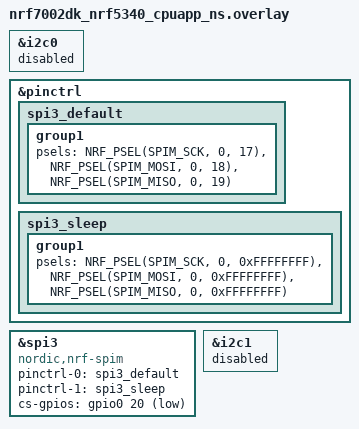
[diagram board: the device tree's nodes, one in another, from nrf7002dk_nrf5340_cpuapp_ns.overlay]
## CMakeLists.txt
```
cmake_minimum_required(VERSION 3.20.0)
find_package(Zephyr REQUIRED HINTS $ENV{ZEPHYR_BASE})
target_include_directories(app PRIVATE ${CMAKE_CURRENT_SOURCE_DIR}/inc)

project(untitled)
set ( SOURCES
      src/main.c
 
)
target_sources(app PRIVATE ${SOURCES})

 
```

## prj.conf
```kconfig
CONFIG_PRINTK=y
CONFIG_SPI=y
CONFIG_GPIO=y
CONFIG_SPI_NRFX=y
```

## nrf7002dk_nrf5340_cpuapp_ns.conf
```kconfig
#UART1 is used for TF-M logging should be disabled
CONFIG_SPI=y
CONFIG_GPIO=y
CONFIG_TFM_SECURE_UART=n
CONFIG_TFM_LOG_LEVEL_SILENCE=y
```

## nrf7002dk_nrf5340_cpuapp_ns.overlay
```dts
/* STEP 2.1 - Add the SPI peripheral to spi1 */
&i2c0 {	status = "disabled";};
//&spi3 {
	//compatible = "nordic,nrf-spim";
    //status = "okay";
    //sck-pin = <17>;  /* SPI Clock Pin */
    //mosi-pin = <18>; /* SPI MOSI Pin */
    //miso-pin = <19>; /* SPI MISO Pin */
    //cs-gpios = <&gpio0 20 GPIO_ACTIVE_LOW>;
//};
//&gpio0 {
//    status = "okay";
//    pinctrl-0 = <&gpio0_pins>;
//    pinctrl-names = "default";
//    cs-gpios = <&gpio0 25 GPIO_ACTIVE_LOW>;  // CS pin, active low
//};

&pinctrl {
    spi3_default: spi3_default {
        group1 {
            psels = <NRF_PSEL(SPIM_SCK, 0, 17)>, /* SCK on pin 17 */
                    <NRF_PSEL(SPIM_MOSI, 0, 18)>, /* MOSI on pin 18 */
                    <NRF_PSEL(SPIM_MISO, 0, 19)>; /* MISO on pin 19 */
        };
    };

    spi3_sleep: spi3_sleep {
        group1 {
            psels = <NRF_PSEL(SPIM_SCK, 0, 0xFFFFFFFF)>, /* Disable SCK */
                    <NRF_PSEL(SPIM_MOSI, 0, 0xFFFFFFFF)>, /* Disable MOSI */
                    <NRF_PSEL(SPIM_MISO, 0, 0xFFFFFFFF)>; /* Disable MISO */
        };
    };
};

&spi3 {
    compatible = "nordic,nrf-spim";
    status = "okay";
    pinctrl-0 = <&spi3_default>;
    pinctrl-1 = <&spi3_sleep>;
    pinctrl-names = "default", "sleep";
    cs-gpios = <&gpio0 20 GPIO_ACTIVE_LOW>; /* Chip Select on GPIO pin 20 */
};


&i2c1 {	status = "disabled";};

/*

&spi1 {
	my_spi_device: my_spi_device@9000 {
      #address-cells = < 0x1 >;
      #size-cells = < 0x0 >;
	    compatible = "nordic,nrf-spim";
      label = "my_spi_device";
		  status = "okay";
		  pinctrl-0 = <&spi1_default>;
		  pinctrl-1 = <&spi1_sleep>;
		  pinctrl-names = "default", "sleep";
      reg = <0x9000 0x1000>;
      interrupts = <0xc 0x1>;
      easydma-maxcnt-bits = < 0x10 >;
      max-frequency= <0x7a1200>;
	  cs-gpios = <&gpio0 5 GPIO_ACTIVE_LOW>;
	};
};

&pinctrl {
	spi1_default: spi1_default {
	cs-gpios = <&gpio0 5 GPIO_ACTIVE_LOW>;
		group1 {
				psels = <NRF_PSEL(SPIM_SCK, 0, 6)>,
						<NRF_PSEL(SPIM_MOSI, 0, 7)>,
						<NRF_PSEL(SPIM_MISO, 0, 26)>;
		};
	};

	spi1_sleep: spi1_sleep {
		group1 {
				psels = <NRF_PSEL(SPIM_SCK, 0, 6)>,
						<NRF_PSEL(SPIM_MOSI, 0, 7)>,
						<NRF_PSEL(SPIM_MISO, 0, 26)>;
				low-power-enable;
		};
	};
};
&gpio0 {
    label = "GPIO_0";
    status = "okay";
};
&gpio1 {
	status = "okay";
    my_gpio: gpio_label {
		gpio-pin = <1>;
		gpio-output-high;
        gpios = <&gpio1 1 GPIO_OUTPUT_HIGH>;
    };
};
*/
```

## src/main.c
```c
#include <zephyr/kernel.h>
#include <zephyr/device.h>
#include <zephyr/drivers/spi.h>
#include <zephyr/drivers/gpio.h>
#include <zephyr/logging/log.h>

/* Logging module (optional, for debug) */
LOG_MODULE_REGISTER(spi_example, LOG_LEVEL_INF);

/* SPI and GPIO configuration */
#define SPI_DEV DT_LABEL(DT_NODELABEL(spi3)) /* SPI3 or your chosen SPI peripheral */
#define CS_GPIO_PORT DT_GPIO_LABEL(DT_NODELABEL(spi3), cs_gpios)
#define CS_GPIO_PIN DT_GPIO_PIN(DT_NODELABEL(spi3), cs_gpios)
#define CS_GPIO_FLAGS DT_GPIO_FLAGS(DT_NODELABEL(spi3), cs_gpios)

/* SPI Configuration */
static const struct spi_cs_control spi_cs = {
    .gpio = GPIO_DT_SPEC_GET(DT_NODELABEL(spi3), cs_gpios),
    .delay = 0,
};

static const struct spi_config spi_cfg = {
    .frequency = 10000, /* 1 MHz */
    .operation = SPI_WORD_SET(8) | SPI_TRANSFER_MSB | SPI_OP_MODE_MASTER,
    .slave = 0,
    .cs = &spi_cs,
};

/* SPI device */
const struct device *spi_dev;

/* Initialize SPI and CS GPIO */
void spi_init(void)
{
    /* Get SPI device */
    spi_dev = DEVICE_DT_GET(DT_NODELABEL(spi3));
    if (!device_is_ready(spi_dev)) {
        LOG_ERR("SPI device not ready");
        return;
    }

    /* Configure CS GPIO */
    const struct gpio_dt_spec cs_spec = GPIO_DT_SPEC_GET(DT_NODELABEL(spi3), cs_gpios);
    if (!device_is_ready(cs_spec.port)) {
        LOG_ERR("CS GPIO device not ready");
        return;
    }

    gpio_pin_configure(cs_spec.port, cs_spec.pin, GPIO_OUTPUT_INACTIVE | cs_spec.dt_flags);

    LOG_INF("SPI initialized with CS active low");
}

/* Perform SPI transfer */
void spi_transfer(void)
{
    uint8_t tx_data[] = {0xAA, 0xBB, 0xCC}; /* Data to send */
    uint8_t rx_data[sizeof(tx_data)] = {0};

    const struct spi_buf tx_buf = {
        .buf = tx_data,
        .len = sizeof(tx_data),
    };
    const struct spi_buf rx_buf = {
        .buf = rx_data,
        .len = sizeof(rx_data),
    };

    const struct spi_buf_set tx = {
        .buffers = &tx_buf,
        .count = 1,
    };
    const struct spi_buf_set rx = {
        .buffers = &rx_buf,
        .count = 1,
    };

    if (spi_transceive(spi_dev, &spi_cfg, &tx, &rx) == 0) {
        LOG_INF("SPI Transfer successful");
        LOG_HEXDUMP_INF(rx_data, sizeof(rx_data), "Received Data");
    } else {
        LOG_ERR("SPI Transfer failed");
    }
}

void main(void)
{
    /* Initialize SPI */
    spi_init();

    /* Perform a transfer */
    while (1) {
        spi_transfer();
        k_sleep(K_MSEC(1000)); /* Delay 1 second */
    }
}
```

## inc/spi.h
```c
#ifndef SPI_DRIVER_H_
#define SPI_DRIVER_H_

#include <zephyr/device.h>
#include <zephyr/drivers/spi.h>
#include <zephyr/drivers/gpio.h>

//#define SPI_CS_PIN     25 // Chip Select pin (adjust based on your setup)
//#define SPI_CS_PORT    DT_LABEL(DT_NODELABEL(gpio0))  // Adjust based on your GPIO port
//#define SPI_FREQ       500000 // SPI frequency in Hz (adjust as needed)
//
//// SPI Device configuration
//extern const struct device *spi_dev;
//extern struct spi_config spi_cfg;
//
//int spi_init(void);
//int spi_transmit(const uint8_t *tx_buf, uint8_t *rx_buf, size_t len);

#endif /* SPI_DRIVER_H_ */
```
